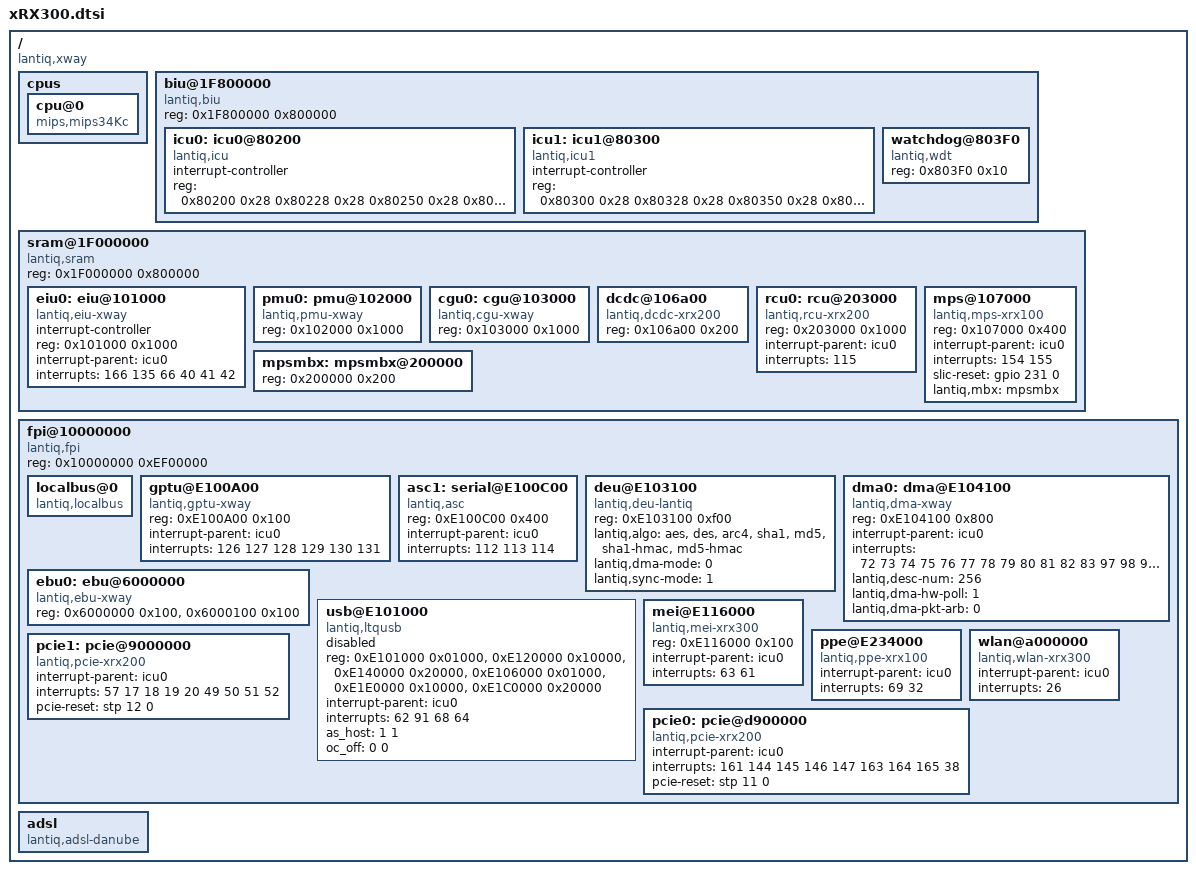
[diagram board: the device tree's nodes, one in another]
/ {
	#address-cells = <1>;
	#size-cells = <1>;
	compatible = "lantiq,xway", "lantiq,ar10";

	cpus {
		cpu@0 {
			compatible = "mips,mips34Kc";
		};
	};

	biu@1F800000 {
		#address-cells = <1>;
		#size-cells = <1>;
		compatible = "lantiq,biu", "simple-bus";
		reg = <0x1F800000 0x800000>;
		ranges = <0x0 0x1F800000 0x7FFFFF>;

		icu0: icu0@80200 {
			#interrupt-cells = <1>;
			interrupt-controller;
			compatible = "lantiq,icu";
			reg = <0x80200 0x28
				0x80228 0x28
				0x80250 0x28
				0x80278 0x28
				0x802a0 0x28>;
		};

                icu1: icu1@80300 {
                        #interrupt-cells = <1>;
                        interrupt-controller;
                        compatible = "lantiq,icu1";
                        reg = <0x80300 0x28
                                0x80328 0x28
                                0x80350 0x28
                                0x80378 0x28
                                0x803a0 0x28>;
                };

		watchdog@803F0 {
			compatible = "lantiq,wdt";
			reg = <0x803F0 0x10>;
		};
	};

	sram@1F000000 {
		#address-cells = <1>;
		#size-cells = <1>;
		compatible = "lantiq,sram", "simple-bus";
		reg = <0x1F000000 0x800000>;
		ranges = <0x0 0x1F000000 0x7FFFFF>;

		eiu0: eiu@101000 {
			#interrupt-cells = <1>;
			interrupt-controller;
			compatible = "lantiq,eiu-xway";
			reg = <0x101000 0x1000>;
			interrupt-parent = <&icu0>;
			interrupts = <166 135 66 40 41 42>;
		};

		pmu0: pmu@102000 {
			compatible = "lantiq,pmu-xway";
			reg = <0x102000 0x1000>;
		};

		cgu0: cgu@103000 {
			compatible = "lantiq,cgu-xway";
			reg = <0x103000 0x1000>;
		};

		dcdc@106a00 {
			compatible = "lantiq,dcdc-xrx200";
			reg = <0x106a00 0x200>;
		};

		rcu0: rcu@203000 {
			compatible = "lantiq,rcu-xrx200";
			reg = <0x203000 0x1000>;
			/* irq for thermal sensor */
			interrupt-parent = <&icu0>;
			interrupts = <115>;
		};

		mps@107000 {
			compatible = "lantiq,mps-xrx100";
			reg = <0x107000 0x400>;
			interrupt-parent = <&icu0>;
			interrupts = <154 155>;
			slic-reset = <&gpio 231 0>;
			lantiq,mbx = <&mpsmbx>;
		};

		mpsmbx: mpsmbx@200000 {
			reg = <0x200000 0x200>;
		};
	};

	fpi@10000000 {
		#address-cells = <1>;
		#size-cells = <1>;
		compatible = "lantiq,fpi", "simple-bus";
		ranges = <0x0 0x10000000 0xEEFFFFF>;
		reg = <0x10000000 0xEF00000>;

		localbus@0 {
			#address-cells = <2>;
			#size-cells = <1>;
			ranges = <0 0 0x0 0x3ffffff /* addrsel0 */
				1 0 0x4000000 0x4000010>; /* addsel1 */
			compatible = "lantiq,localbus", "simple-bus";
		};

		gptu@E100A00 {
			compatible = "lantiq,gptu-xway";
			reg = <0xE100A00 0x100>;
			interrupt-parent = <&icu0>;
                        interrupts = <126 127 128 129 130 131>;
		};

		asc1: serial@E100C00 {
			compatible = "lantiq,asc";
			reg = <0xE100C00 0x400>;
			interrupt-parent = <&icu0>;
			interrupts = <112 113 114>;
		};

		deu@E103100 {
			compatible = "lantiq,deu-lantiq";
			reg = <0xE103100 0xf00>;
			lantiq,algo = "aes", "des", "arc4", "sha1", "md5", "sha1-hmac", "md5-hmac";
			lantiq,dma-mode = <0>;
			lantiq,sync-mode = <1>;
		};

		dma0: dma@E104100 {
			compatible = "lantiq,dma-xway";
			reg = <0xE104100 0x800>;
			interrupt-parent = <&icu0>;
			interrupts = <72 73 74 75 76 77 78 79 80 81 82 83 97 98 99 100 101 70 88 93 136 137 138 139>;
			lantiq,desc-num = <256>;
			lantiq,dma-hw-poll = <1>;
			lantiq,dma-pkt-arb = <0>;
		};

		ebu0: ebu@6000000 {
			compatible = "lantiq,ebu-xway";
			reg = <0x6000000 0x100>,
			      <0x6000100 0x100>;
			reg-names = "ebunand_reg", "hsnand_reg";
		};

		usb@E101000 {
			compatible = "lantiq,ltqusb";
			reg = <0xE101000 0x01000>,
				  <0xE120000 0x10000>,
				  <0xE140000 0x20000>,
				  <0xE106000 0x01000>,
				  <0xE1E0000 0x10000>,
				  <0xE1C0000 0x20000>;
			interrupt-parent = <&icu0>;

			interrupts = <62 91 68 64>; /* interrupt content is USB1 USB2 OC1 OC2 */
			as_host    = <1 1>;
			oc_off     = <0 0>;
			status = "disabled";
		};

		mei@E116000 {
			compatible = "lantiq,mei-xrx300";
			reg = <0xE116000 0x100>;
			interrupt-parent = <&icu0>;
			interrupts = <63 61>;
		};

		ppe@E234000 {
			compatible = "lantiq,ppe-xrx100";
			interrupt-parent = <&icu0>;
			interrupts = <69 32>;
		};

		wlan@a000000 {
			compatible ="lantiq,wlan-xrx300";
			status = "okay";
			interrupt-parent = <&icu0>;
			interrupts = <26>;
		};

		pcie0:pcie@d900000 {
			compatible = "lantiq,pcie-xrx200";
			interrupt-parent = <&icu0>;
			interrupts = <161 144 145 146 147 163 164 165 38>;
			pcie-reset = <&stp 11 0>;
		};

		pcie1:pcie@9000000 {
			compatible = "lantiq,pcie-xrx200";
			interrupt-parent = <&icu0>;
			interrupts = <57 17 18 19 20 49 50 51 52>;
			pcie-reset = <&stp 12 0>;
		};

	};

	adsl {
		compatible = "lantiq,adsl-danube";
	};
};
